# ESP32-H4 register map
Vendor: ESPRESSIF SYSTEMS (SHANGHAI) CO., LTD.; Series: ESP32 H-Series; File version: 1
CPU: RV32IMAC r0p0, little endian, no MPU, no FPU, 0 interrupt priority bits
Address unit: 32 bits
Registers are 32-bit, read-write, reset 0x0 unless marked. A register's access mark holds for its fields unless they carry their own. Offsets are from the block's base; [hi:lo] are bit positions; {n}, {i} and the like mark numbered series.

## EFUSE — eFuse Controller
Base 0x600B1800
{0x0+4i} PGM_DATA{i} (i=0..7) — Represents pgm_data{i}
  [31:0] PGM_DATA — Configures the %sth 32-bit data to be programmed.
{0x20+4i} PGM_CHECK_VALUE{i} (i=0..2) — Represents pgm_check_value{i}
  [31:0] PGM_RS_DATA — Configures the %sth RS code to be programmed.
0x2C RD_WR_DIS0 ro — Represents rd_wr_dis
  [31:0] WR_DIS — Represents whether programming of individual eFuse memory bit is disabled or enabled.\\ 1: Disabled\\ 0: Enabled\\
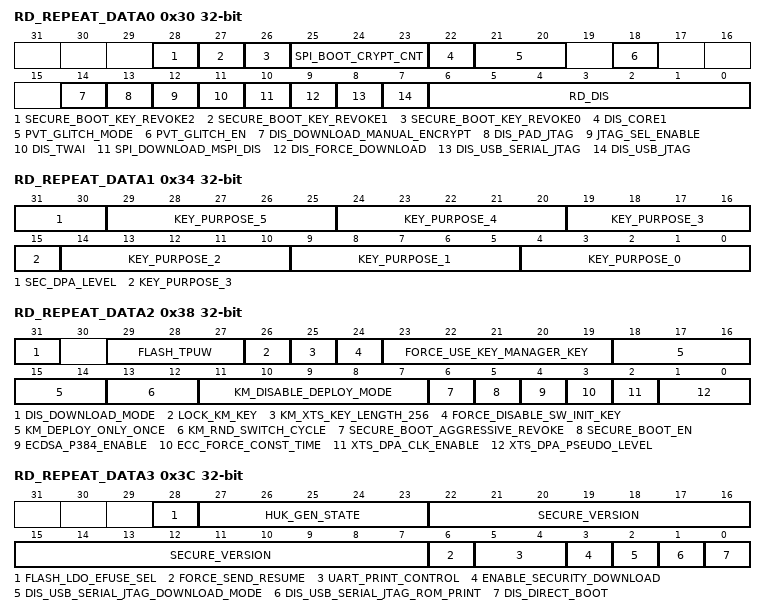
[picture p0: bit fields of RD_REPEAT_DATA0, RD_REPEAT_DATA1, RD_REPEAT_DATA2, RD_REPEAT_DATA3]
0x30 RD_REPEAT_DATA0 ro — Represents rd_repeat_data
  [28] SECURE_BOOT_KEY_REVOKE2 — Represents whether revoking third secure boot key is enabled or disabled.\\ 1: enabled\\ 0: disabled\\
  [27] SECURE_BOOT_KEY_REVOKE1 — Represents whether revoking second secure boot key is enabled or disabled.\\ 1: enabled\\ 0: disabled\\
  [26] SECURE_BOOT_KEY_REVOKE0 — Represents whether revoking first secure boot key is enabled or disabled.\\ 1: enabled\\ 0: disabled\\
  [25:23] SPI_BOOT_CRYPT_CNT — Represents whether SPI boot encrypt/decrypt is disabled or enabled.\\ Odd number of 1: enabled\\ Even number of 1: disabled\\
  [22] DIS_CORE1 — Represents whether the CPU-Core1 is disabled. \\ 1: Disabled. \\ 0: Not disable.
  [21:20] PVT_GLITCH_MODE — Use to configure glitch mode
  [18] PVT_GLITCH_EN — Represents whether to enable PVT power glitch monitor function.\\1:Enable. \\0:Disable
  [14] DIS_DOWNLOAD_MANUAL_ENCRYPT — Represents whether flash encrypt function is disabled or enabled(except in SPI boot mode).\\ 1: disabled\\ 0: enabled\\
  [13] DIS_PAD_JTAG — Represents whether JTAG is disabled in the hard way(permanently).\\ 1: disabled\\ 0: enabled\\
  [12] JTAG_SEL_ENABLE — Represents whether the selection between usb_to_jtag and pad_to_jtag through strapping gpio15 when both EFUSE_DIS_PAD_JTAG and EFUSE_DIS_USB_JTAG are equal to 0 is enabled or disabled.\\ 1: enabled\\ 0: disabled\\
  [11] DIS_TWAI — Represents whether TWAI function is disabled or enabled.\\ 1: disabled\\ 0: enabled\\
  [10] SPI_DOWNLOAD_MSPI_DIS — Represents whether SPI0 controller during boot_mode_download is disabled or enabled.\\ 1: disabled\\ 0: enabled\\
  [9] DIS_FORCE_DOWNLOAD — Represents whether the function that forces chip into download mode is disabled or enabled.\\ 1: disabled\\ 0: enabled\\
  [8] DIS_USB_SERIAL_JTAG — Represents whether USB-Serial-JTAG is disabled or enabled.\\ 1: disabled\\ 0: enabled\\
  [7] DIS_USB_JTAG — Represents whether the function of usb switch to jtag is disabled or enabled.\\ 1: disabled\\ 0: enabled\\
  [6:0] RD_DIS — Represents whether reading of individual eFuse block(block4~block10) is disabled or enabled.\\ 1: disabled\\ 0: enabled\\
0x34 RD_REPEAT_DATA1 ro — Represents rd_repeat_data
  [31:30] SEC_DPA_LEVEL — Represents the spa secure level by configuring the clock random divide mode.
  [5n+4:5n] KEY_PURPOSE_{n} (n=0..5) — Represents the purpose of Key{n}.
0x38 RD_REPEAT_DATA2 ro — Represents rd_repeat_data
  [31] DIS_DOWNLOAD_MODE — Represents whether Download mode is disabled or enabled.\\ 1: disabled\\ 0: enabled\\
  [29:27] FLASH_TPUW — Represents the flash waiting time after power-up, in unit of ms. When the value less than 15, the waiting time is the programmed value. Otherwise, the waiting time is 2 times the programmed value.
  [26] LOCK_KM_KEY — Represents whether the keys in the Key Manager are locked after deployment.\\0: Not locked\\1: Locked\\
  [25] KM_XTS_KEY_LENGTH_256 — Represents which key flash encryption uses.\\0: XTS-AES-256 key\\1: XTS-AES-128 key\\
  [24] FORCE_DISABLE_SW_INIT_KEY — Represents whether to disable the use of the initialization key written by software and instead force use efuse\_init\_key.\\0: Enable\\1: Disable\\
  [23:19] FORCE_USE_KEY_MANAGER_KEY — Represents whether the corresponding key must come from Key Manager. \\Bit0: Represents whether the ECDSA key must come from Key Manager.\\0: The key does not need to come from Key Manager\\1: The key must come from Key Manager\\Bit1: Represents whether the XTS-AES (flash and PSRAM) key must come from Key Manager.\\0: The key does not need to come from Key Manager\\1: The key must come from Key Manager\\Bit2: Represents whether the HMAC key must come from Key Manager.\\0: The key does not need to come from Key Manager\\1: The key must come from Key Manager\\Bit3: Represents whether the DS key must come from Key Manager.\\0: The key does not need to come from Key Manager\\1: The key must come from Key Manager\\
  [18:14] KM_DEPLOY_ONLY_ONCE — Represents whether the corresponding key can be deployed only once.\\Bit0: Represents whether the ECDSA key can be deployed only once\\0: The key can be deployed multiple times\\1: The key can be deployed only once\\Bit1: Represents whether the XTS-AES (flash and PSRAM) key can be deployed only once\\0: The key can be deployed multiple times\\1: The key can be deployed only once\\Bit2: Represents whether the HMAC key can be deployed only once\\0: The key can be deployed multiple times\\1: The key can be deployed only once\\Bit3: Represents whether the DS key can be deployed only once\\0: The key can be deployed multiple times\\1: The key can be deployed only once\\
  [13:12] KM_RND_SWITCH_CYCLE — Represents the cycle at which the Key Manager switches random numbers.\\0: Controlled by the \hyperref[fielddesc:KEYMNGRNDSWITCHCYCLE]{KEYMNG\_RND\_SWITCH\_CYCLE} register. For more information, please refer to Chapter ef{mod:keymng} extit{ ameref{mod:keymng}}\\1: 8 Key Manager clock cycles\\2: 16 Key Manager clock cycles\\3: 32 Key Manager clock cycles\\
  [11:7] KM_DISABLE_DEPLOY_MODE — Represents whether the new key deployment of key manager is disabled. \\Bit0: Represents whether the new ECDSA key deployment is disabled\\0: Enabled\\1: Disabled\\Bit1: Represents whether the new XTS-AES (flash and PSRAM) key deployment is disabled\\0: Enabled\\1: Disabled\\Bit2: Represents whether the new HMAC key deployment is disabled\\0: Enabled\\1: Disabled\\Bit3: Represents whether the new DS key deployment is disabled\\0: Enabled\\1: Disabled\\
  [6] SECURE_BOOT_AGGRESSIVE_REVOKE — Represents whether revoking aggressive secure boot is enabled or disabled.\\ 1: enabled.\\ 0: disabled\\
  [5] SECURE_BOOT_EN — Represents whether secure boot is enabled or disabled.\\ 1: enabled\\ 0: disabled\\
  [4] ECDSA_P384_ENABLE — Represents if the chip supports ECDSA P384
  [3] ECC_FORCE_CONST_TIME — Represents whether to force ecc to use const-time calculation mode. \\ 1: Enable. \\ 0: Disable.
  [2] XTS_DPA_CLK_ENABLE — Represents whether xts-aes anti-dpa attack clock is enabled.\\ 1. Enable.\\ 0: Disable.\\
  [1:0] XTS_DPA_PSEUDO_LEVEL — Represents the pseudo round level of xts-aes anti-dpa attack.\\ 3: High.\\ 2: Moderate 1. Low\\ 0: Disabled\\
0x3C RD_REPEAT_DATA3 ro — Represents rd_repeat_data
  [28] FLASH_LDO_EFUSE_SEL — Represents whether to select efuse control flash ldo default voltage. \\ 1 : efuse 0 : strapping
  [27:23] HUK_GEN_STATE — Represents whether the HUK generate mode is valid.\\Odd count of bits with a value of 1: Invalid\\Even count of bits with a value of 1: Valid\\
  [22:7] SECURE_VERSION — Represents the version used by ESP-IDF anti-rollback feature.
  [6] FORCE_SEND_RESUME — Represents whether ROM code is forced to send a resume command during SPI boot.\\ 1: forced\\ 0:not forced\\
  [5:4] UART_PRINT_CONTROL — Represents the type of UART printing.\\ 00: force enable printing\\ 01: enable printing when GPIO8 is reset at low level\\ 10: enable printing when GPIO8 is reset at high level\\ 11: force disable printing\\
  [3] ENABLE_SECURITY_DOWNLOAD — Represents whether security download is enabled or disabled.\\ 1: enabled\\ 0: disabled\\
  [2] DIS_USB_SERIAL_JTAG_DOWNLOAD_MODE — Represents whether the USB-Serial-JTAG download function is disabled or enabled.\\ 1: Disable\\ 0: Enable\\
  [1] DIS_USB_SERIAL_JTAG_ROM_PRINT — Represents whether print from USB-Serial-JTAG is disabled or enabled.\\ 1: disabled\\ 0: enabled\\
  [0] DIS_DIRECT_BOOT — Represents whether direct boot mode is disabled or enabled.\\ 1: disabled\\ 0: enabled\\
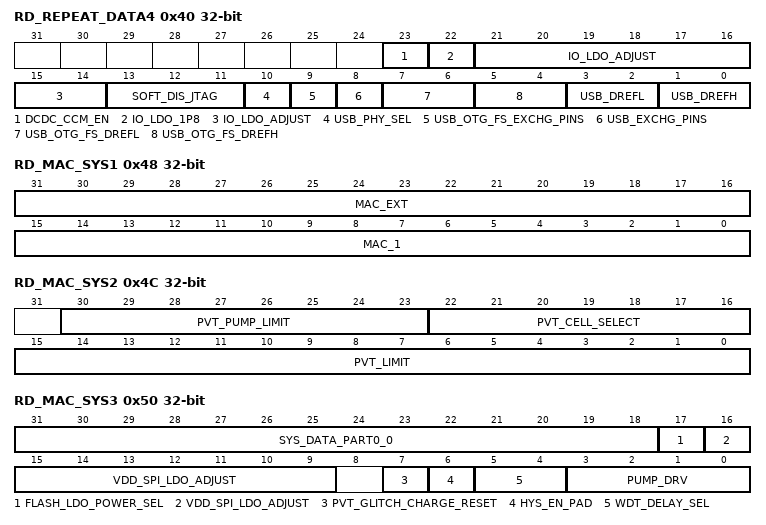
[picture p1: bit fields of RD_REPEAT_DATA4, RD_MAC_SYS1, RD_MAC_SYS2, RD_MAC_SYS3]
0x40 RD_REPEAT_DATA4 ro — Represents rd_repeat_data
  [23] DCDC_CCM_EN — Represents whether change DCDC to CCM mode
  [22] IO_LDO_1P8 — Represents select IO LDO voltage to 1.8V or 3.3V.\\ 1: 1.8V\\ 0: 3.3V\\
  [21:14] IO_LDO_ADJUST — Represents configuration of IO LDO mode and voltage.\\
  [13:11] SOFT_DIS_JTAG — Represents whether JTAG is disabled in soft way.\\ Odd number: disabled\\ Even number: enabled\\
  [10] USB_PHY_SEL — Represents whether to exchange the USB_SERIAL_JTAG PHY with USB_OTG_FS PHY. \\ 1: exchanged. \\ 0: not exchanged.
  [9] USB_OTG_FS_EXCHG_PINS — Represents whether the D+ and D- pins of USB_OTG_FS PHY is exchanged.\\ 1: exchanged\\ 0: not exchanged\\
  [8] USB_EXCHG_PINS — Represents whether the D+ and D- pins of USB_SERIAL_JTAG PHY is exchanged.\\ 1: exchanged\\ 0: not exchanged\\
  [7:6] USB_OTG_FS_DREFL — Represents the single-end input threhold vrefl of USB_OTG_FS PHY, 1.76 V to 2 V with step of 80 mV.
  [5:4] USB_OTG_FS_DREFH — Represents the single-end input threhold vrefh of USB_OTG_FS PHY, 1.76 V to 2 V with step of 80 mV.
  [3:2] USB_DREFL — Represents the single-end input threhold vrefl of USB_SERIAL_JTAG PHY, 1.76 V to 2 V with step of 80 mV.
  [1:0] USB_DREFH — Represents the single-end input threhold vrefh of USB_SERIAL_JTAG PHY, 1.76 V to 2 V with step of 80 mV.
0x44 RD_MAC_SYS0 ro — Represents rd_mac_sys
  [31:0] MAC_0 — Represents MAC address. Low 32-bit.
0x48 RD_MAC_SYS1 ro — Represents rd_mac_sys
  [31:16] MAC_EXT — Represents the extended bits of MAC address.
  [15:0] MAC_1 — Represents MAC address. High 16-bit.
0x4C RD_MAC_SYS2 ro — Represents rd_mac_sys
  [30:23] PVT_PUMP_LIMIT — Use to configure voltage monitor limit for charge pump
  [22:16] PVT_CELL_SELECT — Power glitch monitor PVT cell select.
  [15:0] PVT_LIMIT — Power glitch monitor threthold.
0x50 RD_MAC_SYS3 ro — Represents rd_mac_sys
  [31:18] SYS_DATA_PART0_0 — Represents the first 14-bit of zeroth part of system data.
  [17] FLASH_LDO_POWER_SEL — Represents which flash ldo be select:\\ 1: FLASH LDO 1P2\\ 0 : FLASH LDO 1P8\\
  [16:9] VDD_SPI_LDO_ADJUST — Represents configuration of FLASH LDO mode and voltage.\\
  [7] PVT_GLITCH_CHARGE_RESET — Represents whether to trigger reset or charge pump when PVT power glitch happened.\\1:Trigger charge pump. \\0:Trigger reset
  [6] HYS_EN_PAD — Represents whether the hysteresis function of corresponding PAD is enabled.\\ 1: enabled\\ 0:disabled\\
  [5:4] WDT_DELAY_SEL — Represents the threshold level of the RTC watchdog STG0 timeout.\\ 0: Original threshold configuration value of STG0 *2 \\1: Original threshold configuration value of STG0 *4 \\2: Original threshold configuration value of STG0 *8 \\3: Original threshold configuration value of STG0 *16 \\
  [3:0] PUMP_DRV — Use to configure charge pump voltage gain
0x54 RD_MAC_SYS4 ro — Represents rd_mac_sys
  [31:0] SYS_DATA_PART0_1 — Represents the first 14-bit of zeroth part of system data.
0x58 RD_MAC_SYS5 ro — Represents rd_mac_sys
  [31:0] SYS_DATA_PART0_2 — Represents the second 32-bit of zeroth part of system data.
{0x5C+4i} RD_SYS_PART1_DATA{i} (i=0..7) ro — Represents rd_sys_part1_data{i}
  [31:0] SYS_DATA_PART1 — Represents the zeroth 32-bit of first part of system data.
{0x7C+4i} RD_USR_DATA{i} (i=0..7) ro — Represents rd_usr_data{i}
  [31:0] USR_DATA — Represents the zeroth 32-bit of block3 (user).
{0x9C+4i} RD_KEY0_DATA{i} (i=0..7) ro — Represents rd_key0_data{i}
  [31:0] KEY0_DATA — Represents the zeroth 32-bit of key0.
{0xBC+4i} RD_KEY1_DATA{i} (i=0..7) ro — Represents rd_key1_data{i}
  [31:0] KEY1_DATA — Represents the zeroth 32-bit of key1.
{0xDC+4i} RD_KEY2_DATA{i} (i=0..7) ro — Represents rd_key2_data{i}
  [31:0] KEY2_DATA — Represents the zeroth 32-bit of key2.
{0xFC+4i} RD_KEY3_DATA{i} (i=0..7) ro — Represents rd_key3_data{i}
  [31:0] KEY3_DATA — Represents the zeroth 32-bit of key3.
{0x11C+4i} RD_KEY4_DATA{i} (i=0..7) ro — Represents rd_key4_data{i}
  [31:0] KEY4_DATA — Represents the zeroth 32-bit of key4.
{0x13C+4i} RD_KEY5_DATA{i} (i=0..7) ro — Represents rd_key5_data{i}
  [31:0] KEY5_DATA — Represents the zeroth 32-bit of key5.
{0x15C+4i} RD_SYS_PART2_DATA{i} (i=0..7) ro — Represents rd_sys_part2_data{i}
  [31:0] SYS_DATA_PART2 — Represents the zeroth 32-bit of second part of system data.
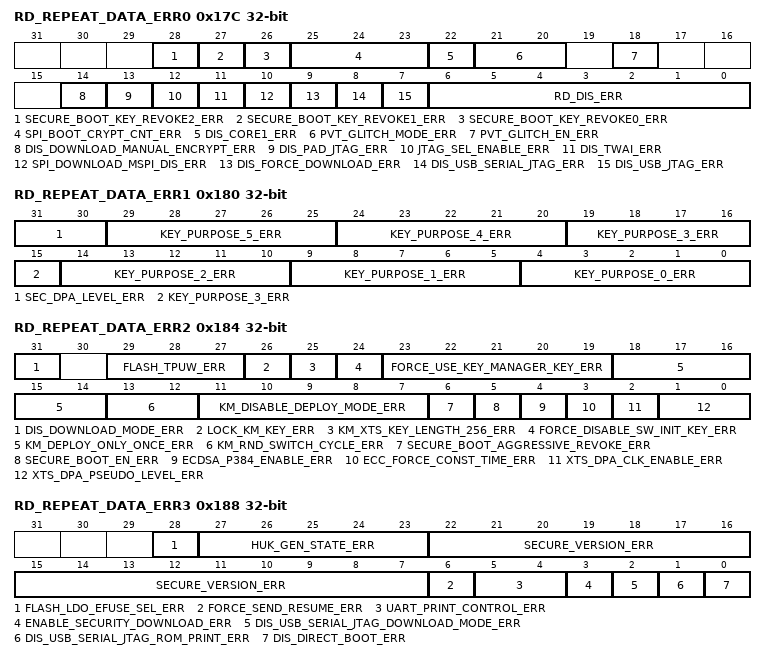
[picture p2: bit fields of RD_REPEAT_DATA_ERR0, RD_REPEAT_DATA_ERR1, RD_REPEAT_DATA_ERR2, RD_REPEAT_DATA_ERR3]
0x17C RD_REPEAT_DATA_ERR0 ro — Represents rd_repeat_data_err
  [28] SECURE_BOOT_KEY_REVOKE2_ERR — Represents the programming error of EFUSE_SECURE_BOOT_KEY_REVOKE2
  [27] SECURE_BOOT_KEY_REVOKE1_ERR — Represents the programming error of EFUSE_SECURE_BOOT_KEY_REVOKE1
  [26] SECURE_BOOT_KEY_REVOKE0_ERR — Represents the programming error of EFUSE_SECURE_BOOT_KEY_REVOKE0
  [25:23] SPI_BOOT_CRYPT_CNT_ERR — Represents the programming error of EFUSE_SPI_BOOT_CRYPT_CNT
  [22] DIS_CORE1_ERR — Represents the programming error of EFUSE_DIS_CORE1
  [21:20] PVT_GLITCH_MODE_ERR — Represents the programming error of EFUSE_PVT_GLITCH_MODE
  [18] PVT_GLITCH_EN_ERR — Represents the programming error of EFUSE_PVT_GLITCH_EN
  [14] DIS_DOWNLOAD_MANUAL_ENCRYPT_ERR — Represents the programming error of EFUSE_DIS_DOWNLOAD_MANUAL_ENCRYPT
  [13] DIS_PAD_JTAG_ERR — Represents the programming error of EFUSE_DIS_PAD_JTAG
  [12] JTAG_SEL_ENABLE_ERR — Represents the programming error of EFUSE_JTAG_SEL_ENABLE
  [11] DIS_TWAI_ERR — Represents the programming error of EFUSE_DIS_TWAI
  [10] SPI_DOWNLOAD_MSPI_DIS_ERR — Represents the programming error of EFUSE_SPI_DOWNLOAD_MSPI_DIS
  [9] DIS_FORCE_DOWNLOAD_ERR — Represents the programming error of EFUSE_DIS_FORCE_DOWNLOAD
  [8] DIS_USB_SERIAL_JTAG_ERR — Represents the programming error of EFUSE_DIS_USB_SERIAL_JTAG
  [7] DIS_USB_JTAG_ERR — Represents the programming error of EFUSE_DIS_USB_JTAG
  [6:0] RD_DIS_ERR — Represents the programming error of EFUSE_RD_DIS
0x180 RD_REPEAT_DATA_ERR1 ro — Represents rd_repeat_data_err
  [31:30] SEC_DPA_LEVEL_ERR — Represents the programming error of EFUSE_SEC_DPA_LEVEL
  [5n+4:5n] KEY_PURPOSE_{n}_ERR (n=0..5) — Represents the programming error of EFUSE_KEY_PURPOSE_{n}
0x184 RD_REPEAT_DATA_ERR2 ro — Represents rd_repeat_data_err
  [31] DIS_DOWNLOAD_MODE_ERR — Represents the programming error of EFUSE_DIS_DOWNLOAD_MODE
  [29:27] FLASH_TPUW_ERR — Represents the programming error of EFUSE_FLASH_TPUW
  [26] LOCK_KM_KEY_ERR — Represents the programming error of EFUSE_LOCK_KM_KEY
  [25] KM_XTS_KEY_LENGTH_256_ERR — Represents the programming error of EFUSE_KM_XTS_KEY_LENGTH_256
  [24] FORCE_DISABLE_SW_INIT_KEY_ERR — Represents the programming error of EFUSE_FORCE_DISABLE_SW_INIT_KEY
  [23:19] FORCE_USE_KEY_MANAGER_KEY_ERR — Represents the programming error of EFUSE_FORCE_USE_KEY_MANAGER_KEY
  [18:14] KM_DEPLOY_ONLY_ONCE_ERR — Represents the programming error of EFUSE_KM_DEPLOY_ONLY_ONCE
  [13:12] KM_RND_SWITCH_CYCLE_ERR — Represents the programming error of EFUSE_KM_RND_SWITCH_CYCLE
  [11:7] KM_DISABLE_DEPLOY_MODE_ERR — Represents the programming error of EFUSE_KM_DISABLE_DEPLOY_MODE
  [6] SECURE_BOOT_AGGRESSIVE_REVOKE_ERR — Represents the programming error of EFUSE_SECURE_BOOT_AGGRESSIVE_REVOKE
  [5] SECURE_BOOT_EN_ERR — Represents the programming error of EFUSE_SECURE_BOOT_EN
  [4] ECDSA_P384_ENABLE_ERR — Represents the programming error of EFUSE_ECDSA_P384_ENABLE
  [3] ECC_FORCE_CONST_TIME_ERR — Represents the programming error of EFUSE_ECC_FORCE_CONST_TIME
  [2] XTS_DPA_CLK_ENABLE_ERR — Represents the programming error of EFUSE_XTS_DPA_CLK_ENABLE
  [1:0] XTS_DPA_PSEUDO_LEVEL_ERR — Represents the programming error of EFUSE_XTS_DPA_PSEUDO_LEVEL
0x188 RD_REPEAT_DATA_ERR3 ro — Represents rd_repeat_data_err
  [28] FLASH_LDO_EFUSE_SEL_ERR — Represents the programming error of EFUSE_FLASH_LDO_EFUSE_SEL
  [27:23] HUK_GEN_STATE_ERR — Represents the programming error of EFUSE_HUK_GEN_STATE
  [22:7] SECURE_VERSION_ERR — Represents the programming error of EFUSE_SECURE_VERSION
  [6] FORCE_SEND_RESUME_ERR — Represents the programming error of EFUSE_FORCE_SEND_RESUME
  [5:4] UART_PRINT_CONTROL_ERR — Represents the programming error of EFUSE_UART_PRINT_CONTROL
  [3] ENABLE_SECURITY_DOWNLOAD_ERR — Represents the programming error of EFUSE_ENABLE_SECURITY_DOWNLOAD
  [2] DIS_USB_SERIAL_JTAG_DOWNLOAD_MODE_ERR — Represents the programming error of EFUSE_DIS_USB_SERIAL_JTAG_DOWNLOAD_MODE
  [1] DIS_USB_SERIAL_JTAG_ROM_PRINT_ERR — Represents the programming error of EFUSE_DIS_USB_SERIAL_JTAG_ROM_PRINT
  [0] DIS_DIRECT_BOOT_ERR — Represents the programming error of EFUSE_DIS_DIRECT_BOOT
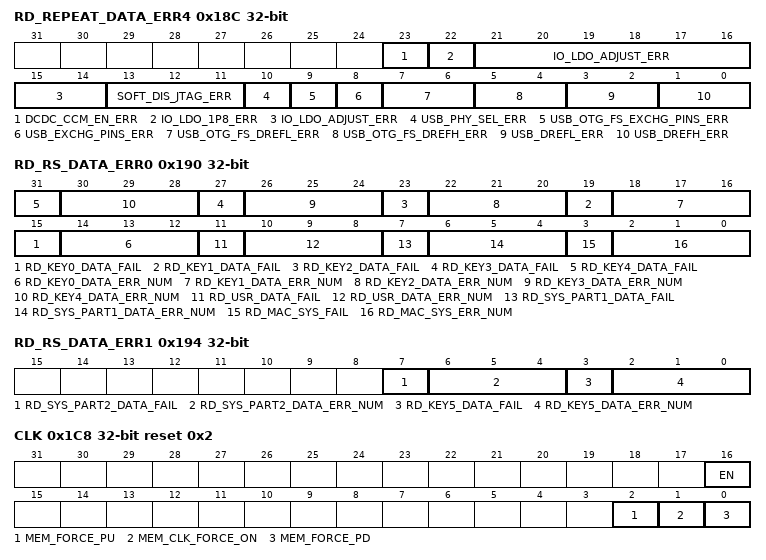
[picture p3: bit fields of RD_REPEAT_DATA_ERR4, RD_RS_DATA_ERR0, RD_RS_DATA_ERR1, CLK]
0x18C RD_REPEAT_DATA_ERR4 ro — Represents rd_repeat_data_err
  [23] DCDC_CCM_EN_ERR — Represents the programming error of EFUSE_DCDC_CCM_EN
  [22] IO_LDO_1P8_ERR — Represents the programming error of EFUSE_IO_LDO_1P8
  [21:14] IO_LDO_ADJUST_ERR — Represents the programming error of EFUSE_IO_LDO_ADJUST
  [13:11] SOFT_DIS_JTAG_ERR — Represents the programming error of EFUSE_SOFT_DIS_JTAG
  [10] USB_PHY_SEL_ERR — Represents the programming error of EFUSE_USB_PHY_SEL
  [9] USB_OTG_FS_EXCHG_PINS_ERR — Represents the programming error of EFUSE_USB_OTG_FS_EXCHG_PINS
  [8] USB_EXCHG_PINS_ERR — Represents the programming error of EFUSE_USB_EXCHG_PINS
  [7:6] USB_OTG_FS_DREFL_ERR — Represents the programming error of EFUSE_USB_OTG_FS_DREFL
  [5:4] USB_OTG_FS_DREFH_ERR — Represents the programming error of EFUSE_USB_OTG_FS_DREFH
  [3:2] USB_DREFL_ERR — Represents the programming error of EFUSE_USB_DREFL
  [1:0] USB_DREFH_ERR — Represents the programming error of EFUSE_USB_DREFH
0x190 RD_RS_DATA_ERR0 ro — Represents rd_rs_data_err
  [4n+15] RD_KEY{n}_DATA_FAIL (n=0..4) — Represents error status of register.\\0: Means no failure and that the data of rd_key{n}_data is reliable\\ 1: Means that programming rd_key{n}_data failed and the number of error bytes is over 6.
  [4n+14:4n+12] RD_KEY{n}_DATA_ERR_NUM (n=0..4) — Represents the error number of registers.\\The value of this signal means the number of error bytes in rd_key{n}_data
  [11] RD_USR_DATA_FAIL — Represents error status of register.\\0: Means no failure and that the data of rd_usr_data is reliable\\ 1: Means that programming rd_usr_data failed and the number of error bytes is over 6.
  [10:8] RD_USR_DATA_ERR_NUM — Represents the error number of registers.\\The value of this signal means the number of error bytes in rd_usr_data
  [7] RD_SYS_PART1_DATA_FAIL — Represents error status of register.\\0: Means no failure and that the data of rd_sys_part1_data is reliable\\ 1: Means that programming rd_sys_part1_data failed and the number of error bytes is over 6.
  [6:4] RD_SYS_PART1_DATA_ERR_NUM — Represents the error number of registers.\\The value of this signal means the number of error bytes in rd_sys_part1_data
  [3] RD_MAC_SYS_FAIL — Represents error status of register.\\0: Means no failure and that the data of rd_mac_sys is reliable\\ 1: Means that programming rd_mac_sys failed and the number of error bytes is over 6.
  [2:0] RD_MAC_SYS_ERR_NUM — Represents the error number of registers.\\The value of this signal means the number of error bytes in rd_mac_sys
0x194 RD_RS_DATA_ERR1 ro — Represents rd_rs_data_err
  [7] RD_SYS_PART2_DATA_FAIL — Represents error status of register.\\0: Means no failure and that the data of rd_sys_part2_data is reliable\\ 1: Means that programming rd_sys_part2_data failed and the number of error bytes is over 6.
  [6:4] RD_SYS_PART2_DATA_ERR_NUM — Represents the error number of registers.\\The value of this signal means the number of error bytes in rd_sys_part2_data
  [3] RD_KEY5_DATA_FAIL — Represents error status of register.\\0: Means no failure and that the data of rd_key5_data is reliable\\ 1: Means that programming rd_key5_data failed and the number of error bytes is over 6.
  [2:0] RD_KEY5_DATA_ERR_NUM — Represents the error number of registers.\\The value of this signal means the number of error bytes in rd_key5_data
0x198 DATE reset 0x2501078 — eFuse version register.
  [27:0] DATE — Represents eFuse version. Date:2025-01-07 18:29:09, ScriptRev:4f86fc8055439e38ad20ae9516f64400592b3577
0x1C8 CLK reset 0x2 — eFuse clcok configuration register.
  [16] EN — Configures whether to force enable eFuse register configuration clock signal.\\ 1: Force\\ 0: The clock is enabled only during the reading and writing of registers\\
  [2] MEM_FORCE_PU — Configures whether to force power up eFuse SRAM.\\ 1: Force\\ 0: No effect\\
  [1] MEM_CLK_FORCE_ON — Configures whether to force activate clock signal of eFuse SRAM.\\ 1: Force activate\\ 0: No effect\\
  [0] MEM_FORCE_PD — Configures whether to force power down eFuse SRAM.\\ 1: Force\\ 0: No effect\\
0x1CC CONF — eFuse operation mode configuraiton register
  [15:0] OP_CODE — Configures operation command type.\\ 0x5A5A: Program operation command\\ 0x5AA5: Read operation command\\ Other values: No effect\\
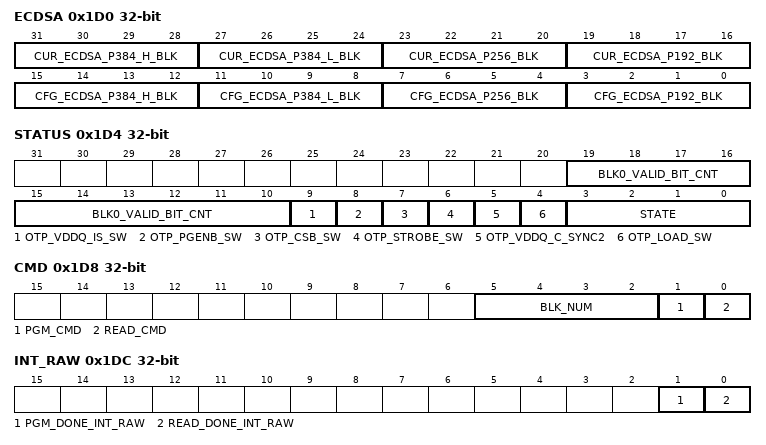
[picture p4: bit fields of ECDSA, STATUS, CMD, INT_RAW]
0x1D0 ECDSA access per field — eFuse status register.
  [31:28] CUR_ECDSA_P384_H_BLK ro — Represents which block is used for ECDSA P384 key high part output.
  [27:24] CUR_ECDSA_P384_L_BLK ro — Represents which block is used for ECDSA P384 key low part output.
  [23:20] CUR_ECDSA_P256_BLK ro — Represents which block is used for ECDSA P256 key output.
  [19:16] CUR_ECDSA_P192_BLK ro — Represents which block is used for ECDSA P192 key output.
  [15:12] CFG_ECDSA_P384_H_BLK rw — Configures which block to use for ECDSA P256 key high part output.
  [11:8] CFG_ECDSA_P384_L_BLK rw — Configures which block to use for ECDSA P384 key low part output.
  [7:4] CFG_ECDSA_P256_BLK rw — Configures which block to use for ECDSA P256 key output.
  [3:0] CFG_ECDSA_P192_BLK rw — Configures which block to use for ECDSA P192 key output.
0x1D4 STATUS ro — eFuse status register.
  [19:10] BLK0_VALID_BIT_CNT — Represents the number of block valid bit.
  [9] OTP_VDDQ_IS_SW — Represents the value of OTP_VDDQ_IS_SW.
  [8] OTP_PGENB_SW — Represents the value of OTP_PGENB_SW.
  [7] OTP_CSB_SW — Represents the value of OTP_CSB_SW.
  [6] OTP_STROBE_SW — Represents the value of OTP_STROBE_SW.
  [5] OTP_VDDQ_C_SYNC2 — Represents the value of OTP_VDDQ_C_SYNC2.
  [4] OTP_LOAD_SW — Represents the value of OTP_LOAD_SW.
  [3:0] STATE — Represents the state of the eFuse state machine.\\ 0: Reset state, the initial state after power-up\\ 1: Idle state\\ Other values: Non-idle state\\
0x1D8 CMD — eFuse command register.
  [5:2] BLK_NUM — Configures the serial number of the block to be programmed. Value 0-10 corresponds to block number 0-10, respectively.
  [1] PGM_CMD — Configures whether to send programing commands.\\ 1: Send\\ 0: No effect\\
  [0] READ_CMD — Configures whether to send read commands.\\ 1: Send\\ 0: No effect\\
0x1DC INT_RAW ro — eFuse raw interrupt register.
  [1] PGM_DONE_INT_RAW — The raw interrupt status of EFUSE_PGM_DONE_INT.
  [0] READ_DONE_INT_RAW — The raw interrupt status of EFUSE_READ_DONE_INT.
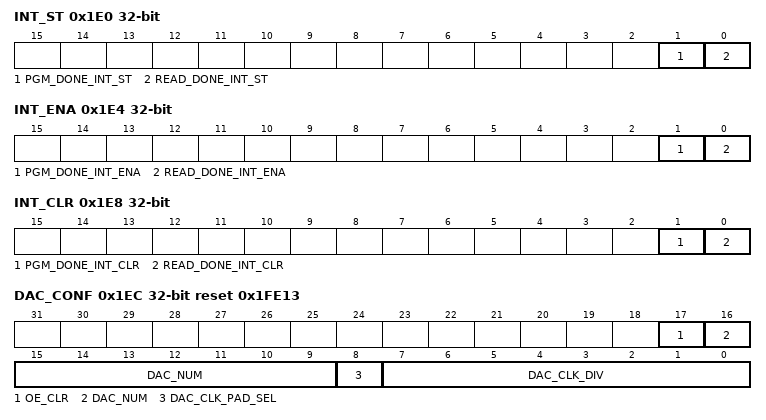
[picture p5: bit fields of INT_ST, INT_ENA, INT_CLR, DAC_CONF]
0x1E0 INT_ST ro — eFuse interrupt status register.
  [1] PGM_DONE_INT_ST — The masked interrupt status of EFUSE_PGM_DONE_INT.
  [0] READ_DONE_INT_ST — The masked interrupt status of EFUSE_READ_DONE_INT.
0x1E4 INT_ENA — eFuse interrupt enable register.
  [1] PGM_DONE_INT_ENA — Write 1 to enable EFUSE_PGM_DONE_INT.
  [0] READ_DONE_INT_ENA — Write 1 to enable EFUSE_READ_DONE_INT.
0x1E8 INT_CLR wo — eFuse interrupt clear register.
  [1] PGM_DONE_INT_CLR — Write 1 to clear EFUSE_PGM_DONE_INT.
  [0] READ_DONE_INT_CLR — Write 1 to clear EFUSE_READ_DONE_INT.
0x1EC DAC_CONF reset 0x1FE13 — Controls the eFuse programming voltage.
  [17] OE_CLR — Configures whether to reduce the power supply of programming voltage.\\ 0: Not reduce\\ 1: Reduce\\
  [16:9] DAC_NUM — Configures clock cycles for programming voltage to rise. Measurement unit: a clock cycle divided by EFUSE_DAC_CLK_DIV.
  [8] DAC_CLK_PAD_SEL — Don't care.
  [7:0] DAC_CLK_DIV — Configures the division factor of the rising clock of the programming voltage.
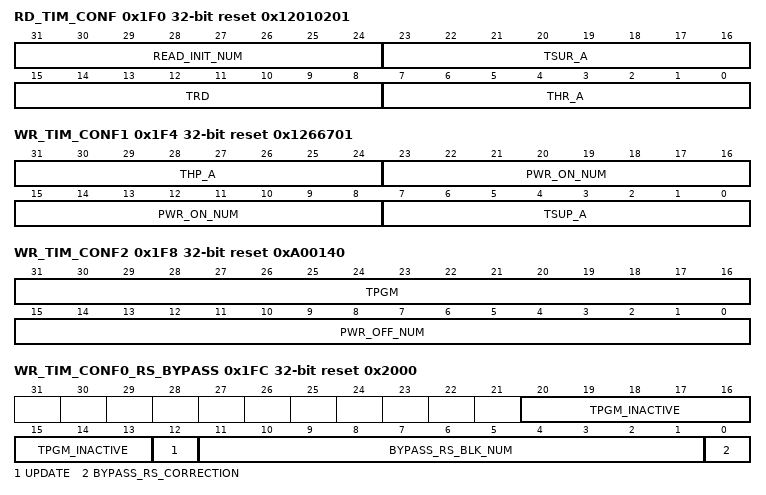
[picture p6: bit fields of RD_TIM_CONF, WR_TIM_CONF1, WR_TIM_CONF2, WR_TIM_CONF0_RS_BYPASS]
0x1F0 RD_TIM_CONF reset 0x12010201 — Configures read timing parameters.
  [31:24] READ_INIT_NUM — Configures the waiting time of reading eFuse memory. Measurement unit: One cycle of the eFuse core clock.
  [23:16] TSUR_A — Configures the read setup time. Measurement unit: One cycle of the eFuse core clock.
  [15:8] TRD — Configures the read time. Measurement unit: One cycle of the eFuse core clock.
  [7:0] THR_A — Configures the read hold time. Measurement unit: One cycle of the eFuse core clock.
0x1F4 WR_TIM_CONF1 reset 0x1266701 — Configurarion register 1 of eFuse programming timing parameters.
  [31:24] THP_A — Configures the programming hold time. Measurement unit: One cycle of the eFuse core clock.
  [23:8] PWR_ON_NUM — Configures the power up time for VDDQ. Measurement unit: One cycle of the eFuse core clock.
  [7:0] TSUP_A — Configures the programming setup time. Measurement unit: One cycle of the eFuse core clock.
0x1F8 WR_TIM_CONF2 reset 0xA00140 — Configurarion register 2 of eFuse programming timing parameters.
  [31:16] TPGM — Configures the active programming time. Measurement unit: One cycle of the eFuse core clock.
  [15:0] PWR_OFF_NUM — Configures the power outage time for VDDQ. Measurement unit: One cycle of the eFuse core clock.
0x1FC WR_TIM_CONF0_RS_BYPASS access per field reset 0x2000 — Configurarion register0 of eFuse programming time parameters and rs bypass operation.
  [20:13] TPGM_INACTIVE rw — Configures the inactive programming time. Measurement unit: One cycle of the eFuse core clock.
  [12] UPDATE wo — Configures whether to update multi-bit register signals.\\ 1: Update\\ 0: No effect\\
  [11:1] BYPASS_RS_BLK_NUM rw — Configures which block number to bypass the Reed-Solomon (RS) correction step.
  [0] BYPASS_RS_CORRECTION rw — Configures whether to bypass the Reed-Solomon (RS) correction step.\\ 0: Not bypass\\ 1: Bypass\\
0x500 APB2OTP_WR_DIS ro — eFuse apb2otp block0 data register1.
  [31:0] APB2OTP_BLOCK0_WR_DIS — Otp block0 write disable data.
{0x500+4i} APB2OTP_BLK0_BACKUP1_W{i} ro (i=1..5) — eFuse apb2otp block0 data register{i+1}.
  [31:0] APB2OTP_BLOCK0_BACKUP1_W{i} — Otp block0 backup1 word{i} data.
{0x514+4i} APB2OTP_BLK0_BACKUP2_W{i} ro (i=1..5) — eFuse apb2otp block0 data register{i+6}.
  [31:0] APB2OTP_BLOCK0_BACKUP2_W{i} — Otp block0 backup2 word{i} data.
{0x528+4i} APB2OTP_BLK0_BACKUP3_W{i} ro (i=1..5) — eFuse apb2otp block0 data register{i+11}.
  [31:0] APB2OTP_BLOCK0_BACKUP3_W{i} — Otp block0 backup3 word{i} data.
{0x53C+4i} APB2OTP_BLK0_BACKUP4_W{i} ro (i=1..5) — eFuse apb2otp block0 data register{i+16}.
  [31:0] APB2OTP_BLOCK0_BACKUP4_W{i} — Otp block0 backup4 word{i} data.
{0x550+4i} APB2OTP_BLK1_W{i} ro (i=1..9) — eFuse apb2otp block1 data register{i}.
  [31:0] APB2OTP_BLOCK1_W{i} — Otp block1 word{i} data.
{0x574+4i} APB2OTP_BLK2_W{i} ro (i=1..11) — eFuse apb2otp block2 data register{i}.
  [31:0] APB2OTP_BLOCK2_W{i} — Otp block2 word{i} data.
{0x5A0+4i} APB2OTP_BLK3_W{i} ro (i=1..11) — eFuse apb2otp block3 data register{i}.
  [31:0] APB2OTP_BLOCK3_W{i} — Otp block3 word{i} data.
0x5D0 APB2OTP_BLK4_W1 ro — eFuse apb2otp BLOCK7 data register1.
  [31:0] APB2OTP_BLOCK4_W1 — Otp block4 word1 data.
{0x5CC+4i} APB2OTP_BLK4_W{i} ro (i=2..9) — eFuse apb2otp block4 data register{i}.
  [31:0] APB2OTP_BLOCK4_W{i} — Otp block4 word{i} data.
0x5F4 APB2OTP_BLK4_W10 ro — eFuse apb2otp block4 data registe10.
  [31:0] APB2OTP_BLOCK4_W10 — Otp block4 word10 data.
0x5F8 APB2OTP_BLK4_W11 ro — eFuse apb2otp block4 data register11.
  [31:0] APB2OTP_BLOCK4_W11 — Otp block4 word11 data.
{0x5F8+4i} APB2OTP_BLK5_W{i} ro (i=1..11) — eFuse apb2otp block5 data register{i}.
  [31:0] APB2OTP_BLOCK5_W{i} — Otp block5 word{i} data.
{0x624+4i} APB2OTP_BLK6_W{i} ro (i=1..11) — eFuse apb2otp block6 data register{i}.
  [31:0] APB2OTP_BLOCK6_W{i} — Otp block6 word{i} data.
{0x650+4i} APB2OTP_BLK7_W{i} ro (i=1..11) — eFuse apb2otp block7 data register{i}.
  [31:0] APB2OTP_BLOCK7_W{i} — Otp block7 word{i} data.
{0x67C+4i} APB2OTP_BLK8_W{i} ro (i=1..11) — eFuse apb2otp block8 data register{i}.
  [31:0] APB2OTP_BLOCK8_W{i} — Otp block8 word{i} data.
{0x6A8+4i} APB2OTP_BLK9_W{i} ro (i=1..11) — eFuse apb2otp block9 data register{i}.
  [31:0] APB2OTP_BLOCK9_W{i} — Otp block9 word{i} data.
{0x6D4+4i} APB2OTP_BLK10_W{i} ro (i=1..11) — eFuse apb2otp block10 data register{i}.
  [31:0] APB2OTP_BLOCK10_W{i} — Otp block10 word{i} data.
0x708 APB2OTP_EN — eFuse apb2otp enable configuration register.
  [0] APB2OTP_APB2OTP_EN — Apb2otp mode enable signal.
